AUTOSAR XML (schema 00047)
package /AUTOSAR/ApComponents
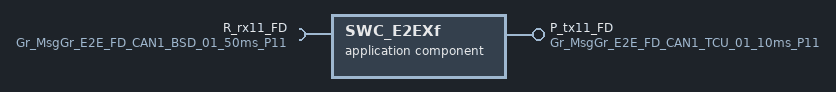
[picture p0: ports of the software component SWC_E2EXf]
  application sw component type SWC_E2EXf
    require port R_rx11_FD: nonqueued-receiver-com-spec=data-element=MsgGr_E2E_FD_CAN1_BSD_01_50ms_P11, required-interface=Gr_MsgGr_E2E_FD_CAN1_BSD_01_50ms_P11
    provide port P_tx11_FD: nonqueued-sender-com-spec=data-element=MsgGr_E2E_FD_CAN1_TCU_01_10ms_P11, provided-interface=Gr_MsgGr_E2E_FD_CAN1_TCU_01_10ms_P11
    behavior InternalBehavior: handle-termination-and-restart=NO-SUPPORT, port-api-option{enable-take-address=false, error-handling=TRANSFORMER-ERROR-HANDLING, indirect-api=false, port=R_rx11_FD}
